# PY32T020xx register map
Vendor: Puya; Series: PY32L0; File version: 1.0.0
CPU: CM0+ r0p1, little endian, no MPU, no FPU, 4 interrupt priority bits
Registers are 32-bit, read-write, reset 0x0 unless marked. A register's access mark holds for its fields unless they carry their own. Offsets are from the block's base; [hi:lo] are bit positions; {n}, {i} and the like mark numbered series.

## FLASH
Base 0x40022000
0x00 ACR
  [1:0] LATENCY
    1=0; 2=1
0x08 KEY
  [31:0] KEY wo — Flash CR key
0x0C OPTKEY
  [31:0] OPTKEY wo — Flash Option key
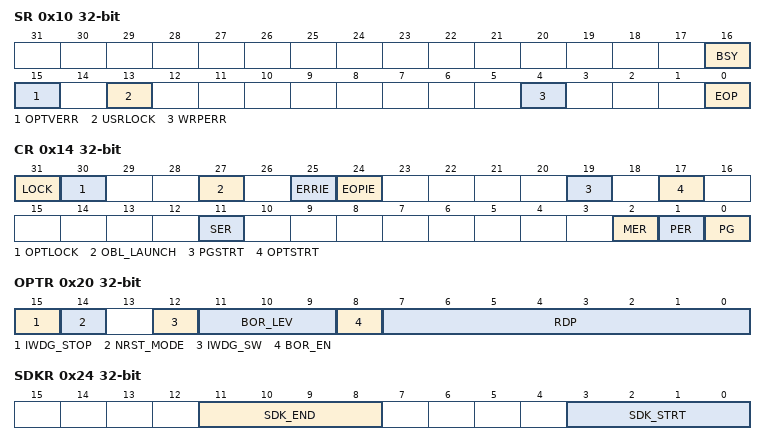
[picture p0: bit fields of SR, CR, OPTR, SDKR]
0x10 SR
  [16] BSY ro — Busy
  [15] OPTVERR — Option and trimming bits loading validity error
  [13] USRLOCK ro — Userdata Lock
  [4] WRPERR — Write protection error
  [0] EOP — End of operation
0x14 CR
  [31] LOCK
  [30] OPTLOCK — Option Lock
  [27] OBL_LAUNCH — Force the option bytes loading
  [25] ERRIE — Error interrupt enable
  [24] EOPIE — End of operation interrupt enable
  [19] PGSTRT — Programming Start
  [17] OPTSTRT — Option bytes Programming Start
  [11] SER — Sector Erase
  [2] MER — Mass Erase
  [1] PER — Page Erase
  [0] PG — Page Program
0x20 OPTR
  [15] IWDG_STOP — IWDG Counting enable in Stop Mode
  [14] NRST_MODE — Pin n_reset Mode
  [12] IWDG_SW — IWDG Software Enable
  [11:9] BOR_LEV — BOR Level
    1=0; 2=1; 4=2
  [8] BOR_EN — BOR enable
  [7:0] RDP — Read Protection
0x24 SDKR
  [11:8] SDK_END — SDK Area End Address
    1=0; 2=1; 4=2; 8=3
  [3:0] SDK_STRT — SDK Area Start Address
    1=0; 2=1; 4=2; 8=3
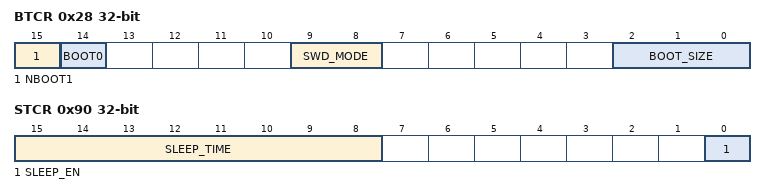
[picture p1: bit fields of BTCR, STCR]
0x28 BTCR
  [15] NBOOT1
  [14] BOOT0
  [9:8] SWD_MODE
    1=0; 2=1
  [2:0] BOOT_SIZE — Load Flash Size
    1=0; 2=1; 4=2
0x2C WRPR
  [7:0] WRP — Write Protection Disable
    1=0; 2=1; 4=2; 8=3; 16=4; 32=5; 64=6; 128=7
0x90 STCR
  [15:8] SLEEP_TIME — FLASH Sleep Time Configuration
  [0] SLEEP_EN — FLASH Sleep Enable
0x100 TS0
  [8:0] TS0
0x104 TS1
  [9:0] TS1
0x108 TS2P
  [8:0] TS2P
0x10C TPS3
  [11:0] TPS3
0x110 TS3
  [8:0] TS3
0x114 PERTPE
  [17:0] PERTPE
0x118 SMERTPE
  [17:0] SMERTPE
0x11C PRGTPE
  [15:0] PRGTPE
0x120 PRETPE
  [13:0] PRETPE

## GPIOA — General-purpose I/Os
Base 0x50000000
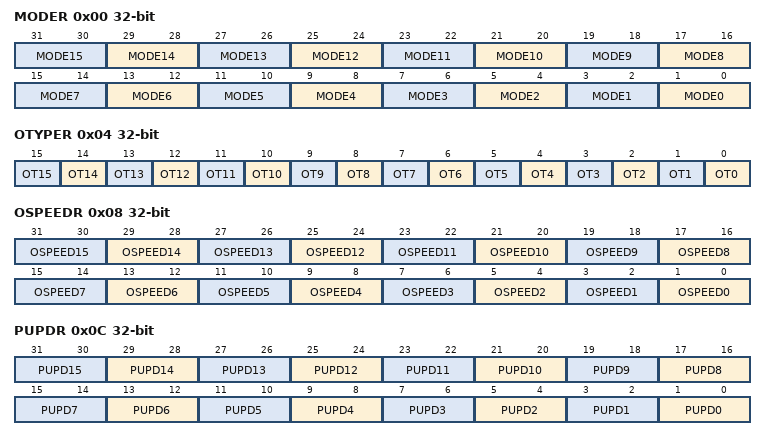
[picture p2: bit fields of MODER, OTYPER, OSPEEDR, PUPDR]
0x00 MODER — GPIO port mode register
  [all] fields
    1=0; 2=1
  [2n+1:2n] MODE{n} (n=0..15) — Port x configuration I/O pin {n}
0x04 OTYPER — GPIO port output type register
  [n] OT{n} (n=0..15) — Port x configuration I/O pin {n}
0x08 OSPEEDR — GPIO port output speed register
  [all] fields
    1=0; 2=1
  [2n+1:2n] OSPEED{n} (n=0..15) — Port x configuration I/O pin {n}
0x0C PUPDR — GPIO port pull-up/pull-down register
  [all] fields
    1=0; 2=1
  [2n+1:2n] PUPD{n} (n=0..15) — Port x configuration I/O pin {n}
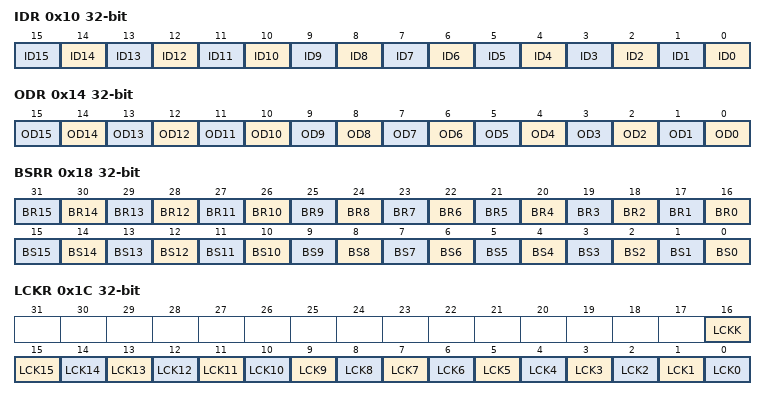
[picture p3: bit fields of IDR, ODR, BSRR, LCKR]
0x10 IDR — GPIO port input data register
  [n] ID{n} ro (n=0..15) — Port x input data I/O pin {n}
0x14 ODR — GPIO port output data register
  [n] OD{n} (n=0..15) — Port output data I/O pin {n}
0x18 BSRR — GPIO port bit set/reset register
  [n+16] BR{n} wo (n=0..15) — Port x reset I/O pin {n}
  [n] BS{n} wo (n=0..15) — Port x set I/O pin {n}
0x1C LCKR — GPIO port configuration lock register
  [16] LCKK — Lock key
  [n] LCK{n} (n=0..15) — Port x lock I/O pin {n}
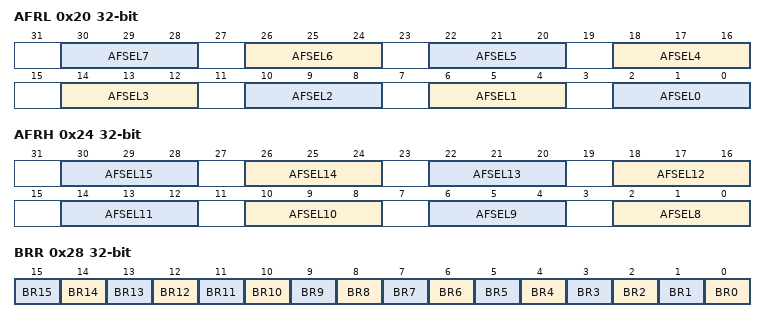
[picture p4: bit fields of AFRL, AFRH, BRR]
0x20 AFRL — GPIO alternate function low register
  [all] fields
    1=0; 2=1; 4=2
  [4n+2:4n] AFSEL{n} (n=4..7) — Alternate function selection for port x I/O pin {n}
  [14:12] AFSEL3 — Alternate function selection for port x I/O pin 4
  [10:8] AFSEL2 — Alternate function selection for port x I/O pin 2
  [6:4] AFSEL1 — Alternate function selection for port x I/O pin 1
  [2:0] AFSEL0 — Alternate function selection for port x I/O pin 0
0x24 AFRH — GPIO alternate function high register
  [all] fields
    1=0; 2=1; 4=2
  [4n-30:4n-32] AFSEL{n} (n=8..15) — Alternate function selection for port x I/O pin {n}
0x28 BRR — port bit reset register
  [n] BR{n} (n=0..15) — Port x reset IO pin {n}

## GPIOB — General-purpose I/Os
Base 0x50000400
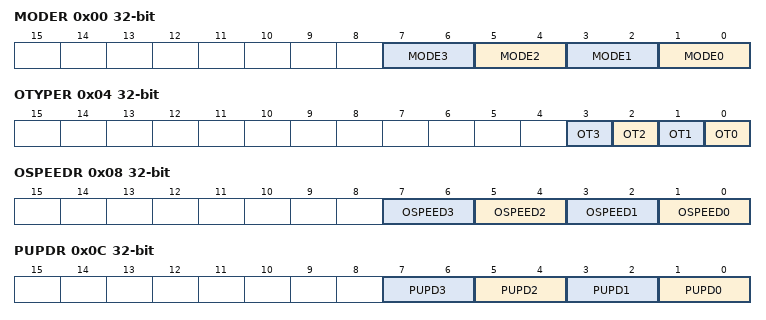
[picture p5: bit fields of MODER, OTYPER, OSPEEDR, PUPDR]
0x00 MODER — GPIO port mode register
  [all] fields
    1=0; 2=1
  [2n+1:2n] MODE{n} (n=0..3) — Port x configuration bits (y = 0..15)
0x04 OTYPER — GPIO port output type register
  [n] OT{n} (n=0..3) — Port x configuration bits (y = 0..15)
0x08 OSPEEDR — GPIO port output speed register
  [all] fields
    1=0; 2=1
  [2n+1:2n] OSPEED{n} (n=0..3) — Port x configuration bits (y = 0..15)
0x0C PUPDR — GPIO port pull-up/pull-down register
  [all] fields
    1=0; 2=1
  [2n+1:2n] PUPD{n} (n=0..3) — Port x configuration bits (y = 0..15)
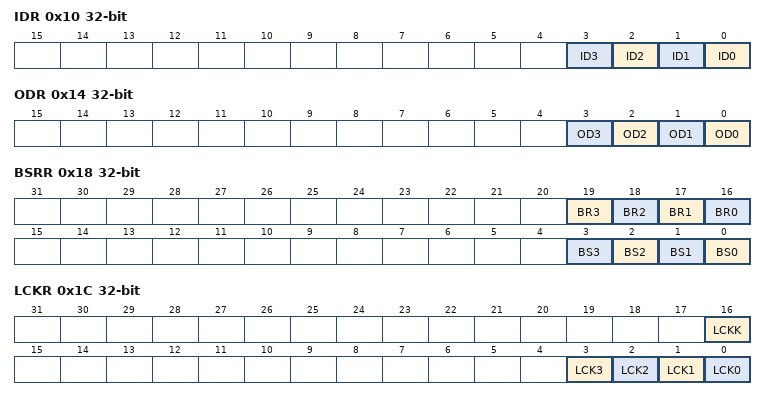
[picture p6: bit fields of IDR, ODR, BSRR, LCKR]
0x10 IDR — GPIO port input data register
  [n] ID{n} ro (n=0..3) — Port input data (y = 0..15)
0x14 ODR — GPIO port output data register
  [n] OD{n} (n=0..3) — Port output data (y = 0..15)
0x18 BSRR — GPIO port bit set/reset register
  [19] BR3 — Port x reset bit y (y = 0..15)
  [18] BR2 — Port x reset bit y (y = 0..15)
  [17] BR1 — Port x reset bit y (y = 0..15)
  [16] BR0 — Port x set bit y (y= 0..15)
  [n] BS{n} (n=0..3) — Port x set bit y (y= 0..15)
0x1C LCKR — GPIO port configuration lock register
  [16] LCKK — Port x lock bit y (y= 0..15)
  [n] LCK{n} (n=0..3) — Port x lock bit y (y= 0..15)
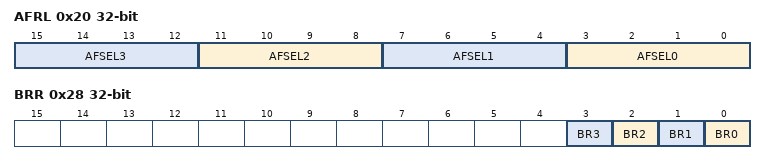
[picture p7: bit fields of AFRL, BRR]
0x20 AFRL — GPIO alternate function low register
  [4n+3:4n] AFSEL{n} (n=0..3) — Alternate function selection for port x bit y (y = 0..7)
0x28 BRR — port bit reset register
  [n] BR{n} (n=0..3) — Port Reset bit
